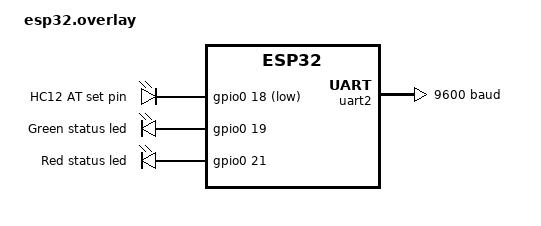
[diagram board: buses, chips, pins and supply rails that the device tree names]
/ {
	aliases {
        green-led = &green_led;
        red-led = &red_led;
        hc12 = &uart2;
        hc12-set = &hc12_set;
        usb = &uart0;
	};

	pins {
		compatible = "gpio-leds";
        hc12_set: hc12_set {
			label = "HC12 AT set pin";
            gpios = <&gpio0 18 GPIO_ACTIVE_LOW>;
        };
    	green_led: green_led {
			label = "Green status led";
            gpios = <&gpio0 19 GPIO_ACTIVE_HIGH>;
        };
        red_led: red_led {
			label = "Red status led";
            gpios = <&gpio0 21 GPIO_ACTIVE_HIGH>;
        };
    };
};

&uart2 {
	status = "okay";
	current-speed = <9600>;
	pinctrl-0 = <&uart2_default>;
	pinctrl-names = "default";
};
